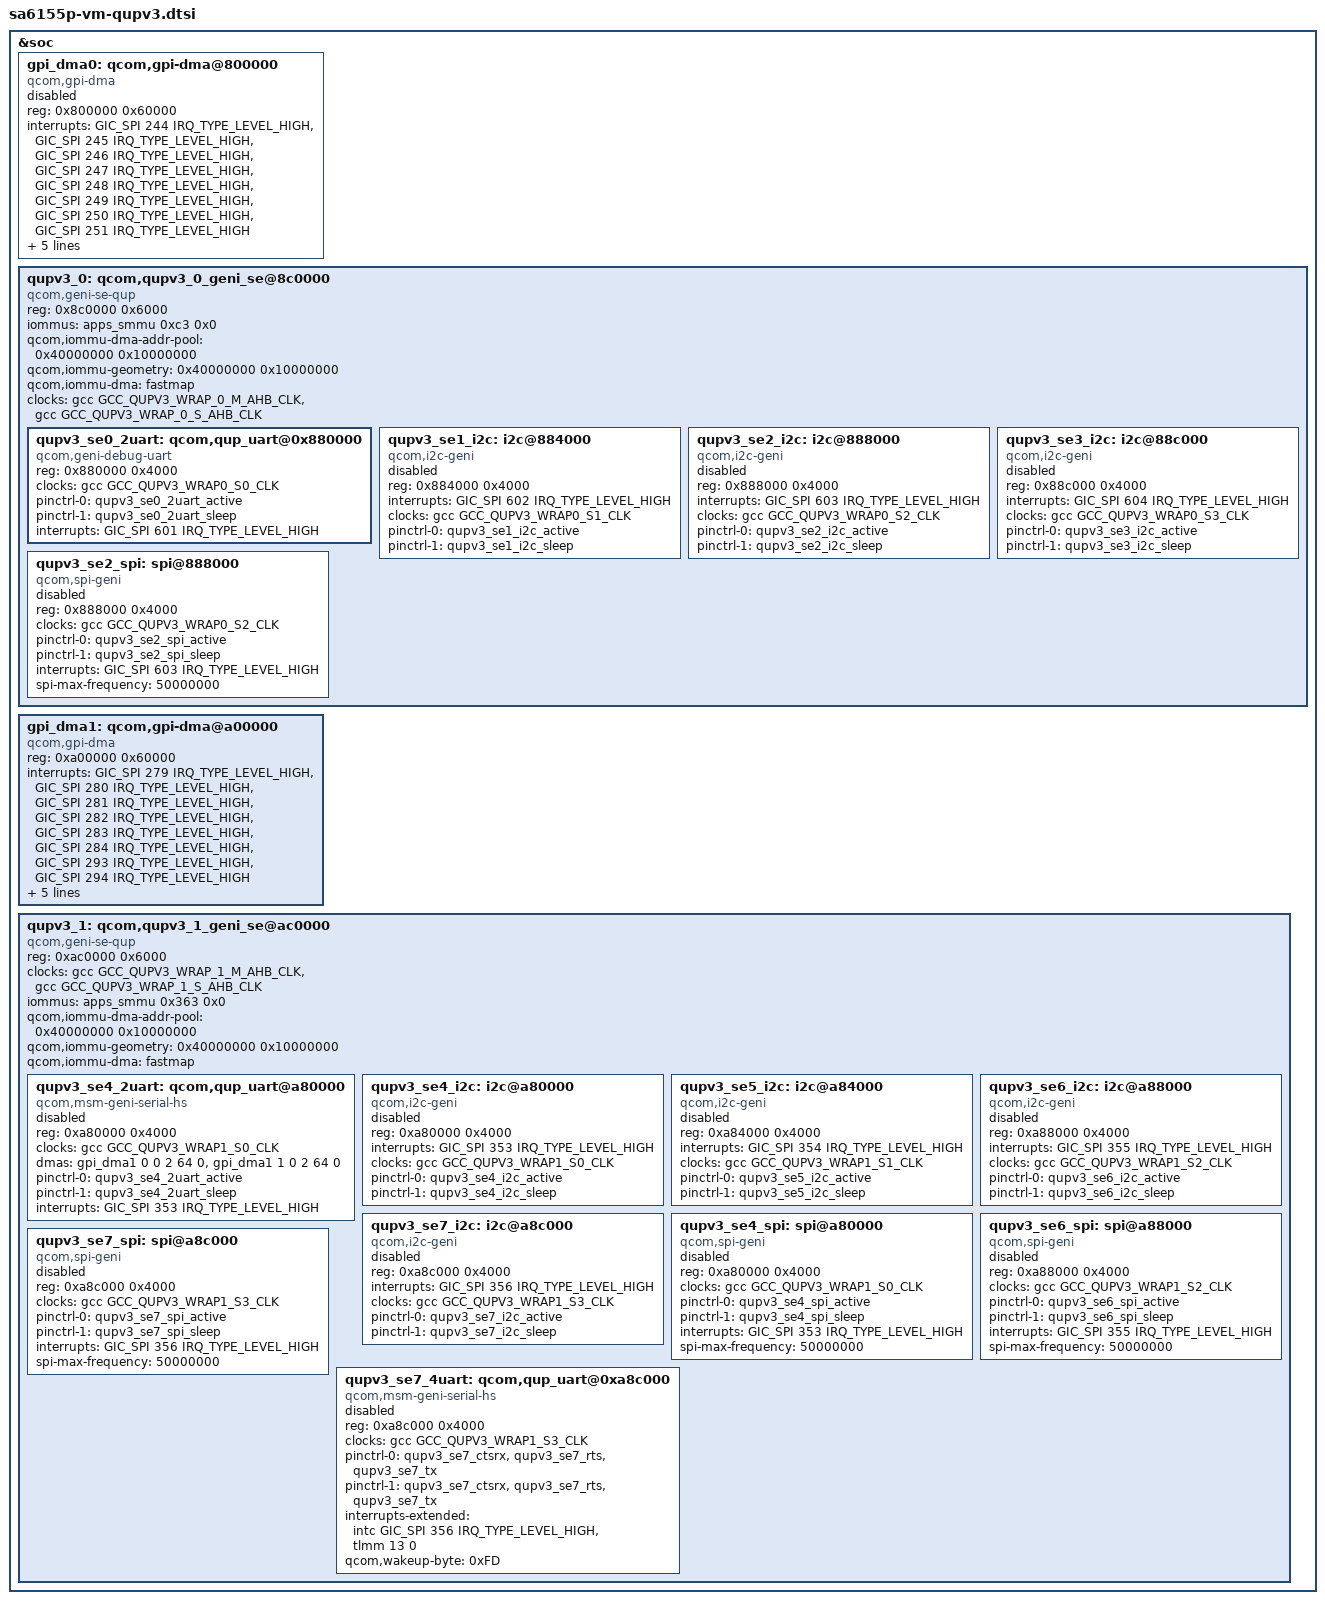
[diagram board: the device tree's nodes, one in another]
&soc {
	/*
	 * QUPv3 North & South Instances
	 * North 0 : SE 4
	 * North 1 : SE 5
	 * North 2 : SE 6
	 * North 3 : SE 7
	 * South 0 : SE 0
	 * South 1 : SE 1
	 * South 2 : SE 2
	 * South 3 : SE 3
	 */

	gpi_dma0: qcom,gpi-dma@800000 {
		compatible = "qcom,gpi-dma";
		#dma-cells = <5>;
		reg = <0x800000 0x60000>;
		reg-names = "gpi-top";
		interrupts = <GIC_SPI 244 IRQ_TYPE_LEVEL_HIGH>,
			<GIC_SPI 245 IRQ_TYPE_LEVEL_HIGH>,
			<GIC_SPI 246 IRQ_TYPE_LEVEL_HIGH>,
			<GIC_SPI 247 IRQ_TYPE_LEVEL_HIGH>,
			<GIC_SPI 248 IRQ_TYPE_LEVEL_HIGH>,
			<GIC_SPI 249 IRQ_TYPE_LEVEL_HIGH>,
			<GIC_SPI 250 IRQ_TYPE_LEVEL_HIGH>,
			<GIC_SPI 251 IRQ_TYPE_LEVEL_HIGH>;
		qcom,max-num-gpii = <8>;
		qcom,gpii-mask = <0x0f>;
		qcom,ev-factor = <2>;
		iommus = <&apps_smmu 0x00d6 0x0>;
		qcom,iommu-dma-addr-pool = <0x100000 0x100000>;
		status = "disabled";
	};

	/* QUPv3 South Instances */
	qupv3_0: qcom,qupv3_0_geni_se@8c0000 {
		compatible = "qcom,geni-se-qup";
		reg = <0x8c0000 0x6000>;
		#address-cells = <1>;
		#size-cells = <1>;
		iommus = <&apps_smmu 0xc3 0x0>;
		qcom,iommu-dma-addr-pool = <0x40000000 0x10000000>;
		qcom,iommu-geometry = <0x40000000 0x10000000>;
		qcom,iommu-dma = "fastmap";
		clock-names = "m-ahb", "s-ahb";
		clocks = <&gcc GCC_QUPV3_WRAP_0_M_AHB_CLK>,
			<&gcc GCC_QUPV3_WRAP_0_S_AHB_CLK>;
		ranges;
		status = "ok";

		/* Debug UART Instance for CDP/MTP platform */
		/* Ported */
		qupv3_se0_2uart: qcom,qup_uart@0x880000 {
			compatible = "qcom,geni-debug-uart";
			reg = <0x880000 0x4000>;
			reg-names = "se_phys";
			clock-names = "se";
			clocks = <&gcc GCC_QUPV3_WRAP0_S0_CLK>;
			pinctrl-names = "default", "sleep";
			pinctrl-0 = <&qupv3_se0_2uart_active>;
			pinctrl-1 = <&qupv3_se0_2uart_sleep>;
			interrupts = <GIC_SPI 601 IRQ_TYPE_LEVEL_HIGH>;
			status = "ok";
		};

		/* I2C */
		qupv3_se1_i2c: i2c@884000 {
			compatible = "qcom,i2c-geni";
			reg = <0x884000 0x4000>;
			interrupts = <GIC_SPI 602 IRQ_TYPE_LEVEL_HIGH>;
			#address-cells = <1>;
			#size-cells = <0>;
			clock-names = "se-clk";
			clocks = <&gcc GCC_QUPV3_WRAP0_S1_CLK>;
			pinctrl-names = "default", "sleep";
			pinctrl-0 = <&qupv3_se1_i2c_active>;
			pinctrl-1 = <&qupv3_se1_i2c_sleep>;
			status = "disabled";
		};

		qupv3_se2_i2c: i2c@888000 {
			compatible = "qcom,i2c-geni";
			reg = <0x888000 0x4000>;
			interrupts = <GIC_SPI 603 IRQ_TYPE_LEVEL_HIGH>;
			#address-cells = <1>;
			#size-cells = <0>;
			clock-names = "se-clk";
			clocks = <&gcc GCC_QUPV3_WRAP0_S2_CLK>;
			pinctrl-names = "default", "sleep";
			pinctrl-0 = <&qupv3_se2_i2c_active>;
			pinctrl-1 = <&qupv3_se2_i2c_sleep>;
			status = "disabled";
		};

		qupv3_se3_i2c: i2c@88c000 {
			compatible = "qcom,i2c-geni";
			reg = <0x88c000 0x4000>;
			interrupts = <GIC_SPI 604 IRQ_TYPE_LEVEL_HIGH>;
			#address-cells = <1>;
			#size-cells = <0>;
			clock-names = "se-clk";
			clocks = <&gcc GCC_QUPV3_WRAP0_S3_CLK>;
			pinctrl-names = "default", "sleep";
			pinctrl-0 = <&qupv3_se3_i2c_active>;
			pinctrl-1 = <&qupv3_se3_i2c_sleep>;
			status = "disabled";
		};

		/* SPI */
		qupv3_se2_spi: spi@888000 {
			compatible = "qcom,spi-geni";
			#address-cells = <1>;
			#size-cells = <0>;
			reg = <0x888000 0x4000>;
			reg-names = "se_phys";
			clock-names = "se-clk";
			clocks = <&gcc GCC_QUPV3_WRAP0_S2_CLK>;
			pinctrl-names = "default", "sleep";
			pinctrl-0 = <&qupv3_se2_spi_active>;
			pinctrl-1 = <&qupv3_se2_spi_sleep>;
			interrupts = <GIC_SPI 603 IRQ_TYPE_LEVEL_HIGH>;
			spi-max-frequency = <50000000>;
			status = "disabled";
		};
	};

	gpi_dma1: qcom,gpi-dma@a00000 {
		compatible = "qcom,gpi-dma";
		#dma-cells = <5>;
		reg = <0xa00000 0x60000>;
		reg-names = "gpi-top";
		interrupts = <GIC_SPI 279 IRQ_TYPE_LEVEL_HIGH>,
			<GIC_SPI 280 IRQ_TYPE_LEVEL_HIGH>,
			<GIC_SPI 281 IRQ_TYPE_LEVEL_HIGH>,
			<GIC_SPI 282 IRQ_TYPE_LEVEL_HIGH>,
			<GIC_SPI 283 IRQ_TYPE_LEVEL_HIGH>,
			<GIC_SPI 284 IRQ_TYPE_LEVEL_HIGH>,
			<GIC_SPI 293 IRQ_TYPE_LEVEL_HIGH>,
			<GIC_SPI 294 IRQ_TYPE_LEVEL_HIGH>;
		qcom,max-num-gpii = <8>;
		qcom,ev-factor = <2>;
		qcom,gpii-mask = <0x0f>;
		iommus = <&apps_smmu 0x0376 0x0>;
		qcom,iommu-dma-addr-pool = <0x100000 0x100000>;
		status = "ok";
	};

	/* QUPv3 North instances */
	qupv3_1: qcom,qupv3_1_geni_se@ac0000 {
		compatible = "qcom,geni-se-qup";
		reg = <0xac0000 0x6000>;
		#address-cells = <1>;
		#size-cells = <1>;
		clock-names = "m-ahb", "s-ahb";
		clocks = <&gcc GCC_QUPV3_WRAP_1_M_AHB_CLK>,
		       <&gcc GCC_QUPV3_WRAP_1_S_AHB_CLK>;
		iommus = <&apps_smmu 0x363 0x0>;
		qcom,iommu-dma-addr-pool = <0x40000000 0x10000000>;
		qcom,iommu-geometry = <0x40000000 0x10000000>;
		qcom,iommu-dma = "fastmap";
		ranges;
		status = "ok";

		/* GNSS UART Instance for CDP/MTP platform */
		qupv3_se4_2uart: qcom,qup_uart@a80000 {
			compatible = "qcom,msm-geni-serial-hs";
			reg = <0xa80000 0x4000>;
			reg-names = "se_phys";
			clock-names = "se-clk";
			clocks = <&gcc GCC_QUPV3_WRAP1_S0_CLK>;
			dmas = <&gpi_dma1 0 0 2 64 0>,
				<&gpi_dma1 1 0 2 64 0>;
			dma-names = "tx", "rx";
			pinctrl-names = "default","sleep";
			pinctrl-0 = <&qupv3_se4_2uart_active>;
			pinctrl-1 = <&qupv3_se4_2uart_sleep>;
			interrupts = <GIC_SPI 353 IRQ_TYPE_LEVEL_HIGH>;
			status = "disabled";
		};

		/* I2C */
		qupv3_se4_i2c: i2c@a80000 {
			compatible = "qcom,i2c-geni";
			reg = <0xa80000 0x4000>;
			interrupts = <GIC_SPI 353 IRQ_TYPE_LEVEL_HIGH>;
			#address-cells = <1>;
			#size-cells = <0>;
			clock-names = "se-clk";
			clocks = <&gcc GCC_QUPV3_WRAP1_S0_CLK>;
			pinctrl-names = "default", "sleep";
			pinctrl-0 = <&qupv3_se4_i2c_active>;
			pinctrl-1 = <&qupv3_se4_i2c_sleep>;
			status = "disabled";
		};

		qupv3_se5_i2c: i2c@a84000 {
			compatible = "qcom,i2c-geni";
			reg = <0xa84000 0x4000>;
			interrupts = <GIC_SPI 354 IRQ_TYPE_LEVEL_HIGH>;
			#address-cells = <1>;
			#size-cells = <0>;
			clock-names = "se-clk";
			clocks = <&gcc GCC_QUPV3_WRAP1_S1_CLK>;
			pinctrl-names = "default", "sleep";
			pinctrl-0 = <&qupv3_se5_i2c_active>;
			pinctrl-1 = <&qupv3_se5_i2c_sleep>;
			status = "disabled";
		};

		qupv3_se6_i2c: i2c@a88000 {
			compatible = "qcom,i2c-geni";
			reg = <0xa88000 0x4000>;
			interrupts = <GIC_SPI 355 IRQ_TYPE_LEVEL_HIGH>;
			#address-cells = <1>;
			#size-cells = <0>;
			clock-names = "se-clk";
			clocks = <&gcc GCC_QUPV3_WRAP1_S2_CLK>;
			pinctrl-names = "default", "sleep";
			pinctrl-0 = <&qupv3_se6_i2c_active>;
			pinctrl-1 = <&qupv3_se6_i2c_sleep>;
			status = "disabled";
		};

		qupv3_se7_i2c: i2c@a8c000 {
			compatible = "qcom,i2c-geni";
			reg = <0xa8c000 0x4000>;
			interrupts = <GIC_SPI 356 IRQ_TYPE_LEVEL_HIGH>;
			#address-cells = <1>;
			#size-cells = <0>;
			clock-names = "se-clk";
			clocks = <&gcc GCC_QUPV3_WRAP1_S3_CLK>;
			pinctrl-names = "default", "sleep";
			pinctrl-0 = <&qupv3_se7_i2c_active>;
			pinctrl-1 = <&qupv3_se7_i2c_sleep>;
			status = "disabled";
		};

		/* SPI */
		qupv3_se4_spi: spi@a80000 {
			compatible = "qcom,spi-geni";
			#address-cells = <1>;
			#size-cells = <0>;
			reg = <0xa80000 0x4000>;
			reg-names = "se_phys";
			clock-names = "se-clk";
			clocks = <&gcc GCC_QUPV3_WRAP1_S0_CLK>;
			pinctrl-names = "default", "sleep";
			pinctrl-0 = <&qupv3_se4_spi_active>;
			pinctrl-1 = <&qupv3_se4_spi_sleep>;
			interrupts = <GIC_SPI 353 IRQ_TYPE_LEVEL_HIGH>;
			spi-max-frequency = <50000000>;
			status = "disabled";
		};

		qupv3_se6_spi: spi@a88000 {
			compatible = "qcom,spi-geni";
			#address-cells = <1>;
			#size-cells = <0>;
			reg = <0xa88000 0x4000>;
			reg-names = "se_phys";
			clock-names = "se-clk";
			clocks = <&gcc GCC_QUPV3_WRAP1_S2_CLK>;
			pinctrl-names = "default", "sleep";
			pinctrl-0 = <&qupv3_se6_spi_active>;
			pinctrl-1 = <&qupv3_se6_spi_sleep>;
			interrupts = <GIC_SPI 355 IRQ_TYPE_LEVEL_HIGH>;
			spi-max-frequency = <50000000>;
			status = "disabled";
		};

		qupv3_se7_spi: spi@a8c000 {
			compatible = "qcom,spi-geni";
			#address-cells = <1>;
			#size-cells = <0>;
			reg = <0xa8c000 0x4000>;
			reg-names = "se_phys";
			clock-names = "se-clk";
			clocks = <&gcc GCC_QUPV3_WRAP1_S3_CLK>;
			pinctrl-names = "default", "sleep";
			pinctrl-0 = <&qupv3_se7_spi_active>;
			pinctrl-1 = <&qupv3_se7_spi_sleep>;
			interrupts = <GIC_SPI 356 IRQ_TYPE_LEVEL_HIGH>;
			spi-max-frequency = <50000000>;
			status = "disabled";
		};

		/*
		 * HS UART instances. HS UART usecases can be supported on these
		 * instances only.
		 */
		qupv3_se7_4uart: qcom,qup_uart@0xa8c000 {
			compatible = "qcom,msm-geni-serial-hs";
			reg = <0xa8c000 0x4000>;
			reg-names = "se_phys";
			clock-names = "se-clk";
			clocks = <&gcc GCC_QUPV3_WRAP1_S3_CLK>;
			pinctrl-names = "default", "sleep";
			pinctrl-0 = <&qupv3_se7_ctsrx>, <&qupv3_se7_rts>,
							<&qupv3_se7_tx>;
			pinctrl-1 = <&qupv3_se7_ctsrx>, <&qupv3_se7_rts>,
							<&qupv3_se7_tx>;
			interrupts-extended = <&intc GIC_SPI 356 IRQ_TYPE_LEVEL_HIGH>,
					<&tlmm 13 0>;
			qcom,wakeup-byte = <0xFD>;
			status = "disabled";
		};
	};
};
